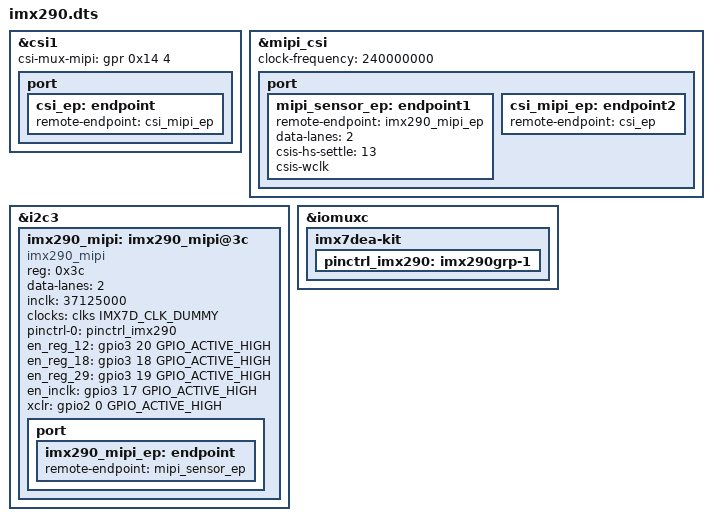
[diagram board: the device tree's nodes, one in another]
&csi1 {
	csi-mux-mipi = <&gpr 0x14 4>;
	status = "okay";

	port {
		csi_ep: endpoint {
			remote-endpoint = <&csi_mipi_ep>;
		};
	};
};

&mipi_csi {
	clock-frequency = <240000000>;
	status = "okay";
	port {
		mipi_sensor_ep: endpoint1 {
			remote-endpoint = <&imx290_mipi_ep>;
			data-lanes = <2>;
			csis-hs-settle = <13>;
			csis-wclk;
		};

		csi_mipi_ep: endpoint2 {
			remote-endpoint = <&csi_ep>;
		};
	};
};


&i2c3 {

        imx290_mipi: imx290_mipi@3c {
                compatible = "imx290_mipi";
                reg = <0x3c>;
                data-lanes = <2>;
                inclk = <37125000>;
                clocks = <&clks IMX7D_CLK_DUMMY>;
                clock-names = "csi_mclk";
                pinctrl-names = "default";
                pinctrl-0 = <&pinctrl_imx290>;
                
                en_reg_12 = <&gpio3 20 GPIO_ACTIVE_HIGH>;
                en_reg_18 = <&gpio3 18 GPIO_ACTIVE_HIGH>;
                en_reg_29 = <&gpio3 19 GPIO_ACTIVE_HIGH>;
                en_inclk =  <&gpio3 17 GPIO_ACTIVE_HIGH>;
                xclr = <&gpio2 0 GPIO_ACTIVE_HIGH>;
                
                port {
                        imx290_mipi_ep: endpoint {
                                remote-endpoint = <&mipi_sensor_ep>;
                        };
                };
        };
};


&iomuxc {
        imx7dea-kit {
		pinctrl_imx290: imx290grp-1 {
		};
        };
};

